AUTOSAR XML (schema 4-2-2)
standard types defined: Double, float64
package /Components
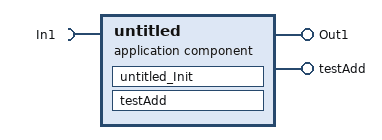
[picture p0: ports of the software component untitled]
  application sw component type untitled
    require port In1: nonqueued-receiver-com-spec{data-element=In1, init-value=0}, required-interface=In1
    provide port Out1: nonqueued-sender-com-spec{data-element=Out1, init-value=0}, provided-interface=Out1
    provide port testAdd: server-com-spec{operation=testAdd, queue-length=1}, provided-interface=testAdd
    behavior untitled_IB: handle-termination-and-restart=NO-SUPPORT
      operation invoked event Event: start-on-event=testAdd, operation=testAdd.testAdd
      runnable untitled_Init
      runnable testAdd
        data-receive-point-by-arguments:
          access IN_In1_In1: accessed-variable=In1.In1
        data-write-access:
          access OUT_Out1_Out1: accessed-variable=Out1.Out1
package /Components/SwcImplementations
  swc implementation untitled_Impl: programming-language=C, sw-version=1.16.1, used-code-generator=Embedded Coder 7.4 (R2020a) 18-Nov-2019, vendor-id=0, behavior=untitled_IB
    code-descriptors:
      code Code
        artifact-descriptors:
          short-label=server_c, category=SWSRC
          short-label=rtwtypes_h, category=SWHDR
          short-label=server_h, category=SWHDR
    resource consumption RsrcCons_server
package /Interfaces
  sender receiver interface In1
    data In1: category=VALUE, sw-calibration-access=READ-ONLY, type=Double
  sender receiver interface Out1
    data Out1: category=VALUE, sw-calibration-access=READ-ONLY, type=Double
  client server interface testAdd
    operation testAdd
      arg u: category=VALUE, sw-calibration-access=READ-ONLY, type=Double, direction=IN
      arg y: category=VALUE, sw-calibration-access=READ-ONLY, type=Double, direction=OUT
package /DataTypes/SwAddrMethods
  sw addr method CODE: section-type=CODE
  sw addr method CONST: section-type=CONST
  sw addr method VAR: section-type=VAR
